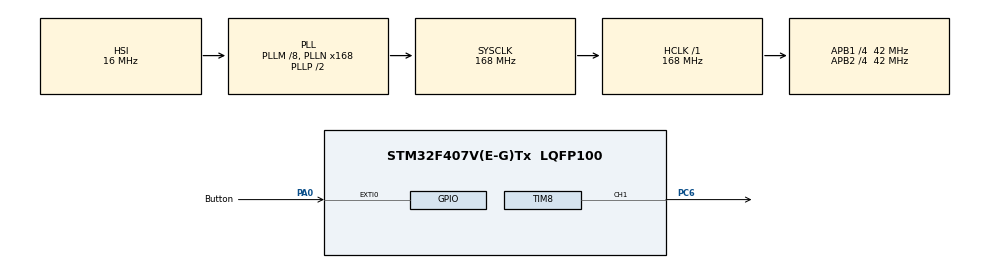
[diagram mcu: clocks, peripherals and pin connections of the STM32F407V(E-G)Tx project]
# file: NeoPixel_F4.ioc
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Dma.Request0=TIM8_CH1
Dma.TIM8_CH1.0.Direction=DMA_MEMORY_TO_PERIPH
Dma.TIM8_CH1.0.FIFOMode=DMA_FIFOMODE_DISABLE
Dma.TIM8_CH1.0.Instance=DMA2_Stream2
Dma.TIM8_CH1.0.MemDataAlignment=DMA_MDATAALIGN_HALFWORD
Dma.TIM8_CH1.0.MemInc=DMA_MINC_ENABLE
Dma.TIM8_CH1.0.Mode=DMA_CIRCULAR
Dma.TIM8_CH1.0.PeriphDataAlignment=DMA_PDATAALIGN_HALFWORD
Dma.TIM8_CH1.0.PeriphInc=DMA_PINC_DISABLE
Dma.TIM8_CH1.0.Priority=DMA_PRIORITY_HIGH
Mcu.Family=STM32F4
Mcu.Name=STM32F407V(E-G)Tx
Mcu.Package=LQFP100
NVIC.DMA2_Stream2_IRQn=true\:0\:0\:false\:false\:true\:false\:true
NVIC.PriorityGroup=NVIC_PRIORITYGROUP_4
PA0-WKUP.GPIO_Label=Button
PA0-WKUP.Signal=GPXTI0
PA13.Mode=Serial_Wire
PA13.Signal=SYS_JTMS-SWDIO
PA14.Mode=Serial_Wire
PA14.Signal=SYS_JTCK-SWCLK
PC14-OSC32_IN.Mode=LSE-External-Oscillator
PC14-OSC32_IN.Signal=RCC_OSC32_IN
PC15-OSC32_OUT.Mode=LSE-External-Oscillator
PC15-OSC32_OUT.Signal=RCC_OSC32_OUT
PC6.GPIO_PuPd=GPIO_PULLDOWN
PC6.GPIO_Speed=GPIO_SPEED_FREQ_HIGH
PC6.Signal=S_TIM8_CH1
PH0-OSC_IN.Mode=HSE-External-Oscillator
PH0-OSC_IN.Signal=RCC_OSC_IN
PH1-OSC_OUT.Mode=HSE-External-Oscillator
PH1-OSC_OUT.Signal=RCC_OSC_OUT
ProjectManager.HeapSize=0x200
ProjectManager.StackSize=0x400
ProjectManager.TargetToolchain=STM32CubeIDE
RCC.48MHZClocksFreq_Value=84000000
RCC.AHBFreq_Value=168000000
RCC.APB1CLKDivider=RCC_HCLK_DIV4
RCC.APB1Freq_Value=42000000
RCC.APB1TimFreq_Value=84000000
RCC.APB2CLKDivider=RCC_HCLK_DIV4
RCC.APB2Freq_Value=42000000
RCC.APB2TimFreq_Value=84000000
RCC.CortexFreq_Value=168000000
RCC.HCLKFreq_Value=168000000
RCC.HSE_VALUE=25000000
RCC.HSI_VALUE=16000000
RCC.PLLM=8
RCC.PLLN=168
RCC.SYSCLKFreq_VALUE=168000000
RCC.SYSCLKSource=RCC_SYSCLKSOURCE_PLLCLK
RCC.VCOOutputFreq_Value=336000000
SH.S_TIM8_CH1.0=TIM8_CH1,PWM Generation1 CH1
TIM8.Channel-PWM\ Generation1\ CH1=TIM_CHANNEL_1
TIM8.OC1Preload_PWM=ENABLE
TIM8.OCFastMode_PWM-PWM\ Generation1\ CH1=TIM_OCFAST_ENABLE
TIM8.OCMode_PWM-PWM\ Generation1\ CH1=TIM_OCMODE_PWM2
TIM8.OCPolarity_1=TIM_OCPOLARITY_LOW
TIM8.Period=104
TIM8.TIM_MasterOutputTrigger=TIM_TRGO_RESET
VP_TIM8_VS_ClockSourceINT.Mode=Internal
board=custom

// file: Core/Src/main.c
/* USER CODE BEGIN Header */
/**
  ******************************************************************************
  * @file           : main.c
  * @brief          : Main program body
  ******************************************************************************
  * @attention
  *
  * <h2><center>&copy; Copyright (c) 2020 STMicroelectronics.
  * All rights reserved.</center></h2>
  *
  * This software component is licensed by ST under BSD 3-Clause license,
  * the "License"; You may not use this file except in compliance with the
  * License. You may obtain a copy of the License at:
  *                        opensource.org/licenses/BSD-3-Clause
  *
  ******************************************************************************
  */
/* USER CODE END Header */
#include "main.h"

/* USER CODE BEGIN Includes */
#include "Neopixel/neopixel.h"
/* USER CODE END Includes */

/* USER CODE BEGIN PD */
#define NUMBERLEDS		5
/* USER CODE END PD */

TIM_HandleTypeDef htim8;
DMA_HandleTypeDef hdma_tim8_ch1;

/* USER CODE BEGIN PV */

uint8_t nums_bit=0;

color database[NUMBERLEDS];

/* USER CODE END PV */

void SystemClock_Config(void);
static void MX_GPIO_Init(void);
static void MX_DMA_Init(void);
static void MX_TIM8_Init(void);

/* USER CODE BEGIN 0 */
void HAL_GPIO_EXTI_Callback(uint16_t GPIO_Pin)
{
	if(GPIO_Pin==GPIO_PIN_0)
	{
		__NOP();
	}
}

/* USER CODE END 0 */

int main(void)
{

  /* MCU Configuration--------------------------------------------------------*/

  /* Reset of all peripherals, Initializes the Flash interface and the Systick. */
  HAL_Init();

  /* Configure the system clock */
  SystemClock_Config();

  /* Initialize all configured peripherals */
  MX_GPIO_Init();
  MX_DMA_Init();
  MX_TIM8_Init();
  /* USER CODE BEGIN 2 */
  init_neopixel(WS2812);
  all_black_render();
  /* USER CODE END 2 */

  /* Infinite loop */
  while (1)
  {

    /* USER CODE BEGIN 3 */
	  if(mode==HALT)
	  {
		  render_rainbow_cycle_mode(5);
	  }
  }
  /* USER CODE END 3 */
}

void SystemClock_Config(void)
{
  RCC_OscInitTypeDef RCC_OscInitStruct = {0};
  RCC_ClkInitTypeDef RCC_ClkInitStruct = {0};

  /** Configure the main internal regulator output voltage
  */
  __HAL_RCC_PWR_CLK_ENABLE();
  __HAL_PWR_VOLTAGESCALING_CONFIG(PWR_REGULATOR_VOLTAGE_SCALE1);
  /** Initializes the RCC Oscillators according to the specified parameters
  * in the RCC_OscInitTypeDef structure.
  */
  RCC_OscInitStruct.OscillatorType = RCC_OSCILLATORTYPE_HSI;
  RCC_OscInitStruct.HSIState = RCC_HSI_ON;
  RCC_OscInitStruct.HSICalibrationValue = RCC_HSICALIBRATION_DEFAULT;
  RCC_OscInitStruct.PLL.PLLState = RCC_PLL_ON;
  RCC_OscInitStruct.PLL.PLLSource = RCC_PLLSOURCE_HSI;
  RCC_OscInitStruct.PLL.PLLM = 8;
  RCC_OscInitStruct.PLL.PLLN = 168;
  RCC_OscInitStruct.PLL.PLLP = RCC_PLLP_DIV2;
  RCC_OscInitStruct.PLL.PLLQ = 4;
  if (HAL_RCC_OscConfig(&RCC_OscInitStruct) != HAL_OK)
  {
    Error_Handler();
  }
  /** Initializes the CPU, AHB and APB buses clocks
  */
  RCC_ClkInitStruct.ClockType = RCC_CLOCKTYPE_HCLK|RCC_CLOCKTYPE_SYSCLK
                              |RCC_CLOCKTYPE_PCLK1|RCC_CLOCKTYPE_PCLK2;
  RCC_ClkInitStruct.SYSCLKSource = RCC_SYSCLKSOURCE_PLLCLK;
  RCC_ClkInitStruct.AHBCLKDivider = RCC_SYSCLK_DIV1;
  RCC_ClkInitStruct.APB1CLKDivider = RCC_HCLK_DIV4;
  RCC_ClkInitStruct.APB2CLKDivider = RCC_HCLK_DIV4;

  if (HAL_RCC_ClockConfig(&RCC_ClkInitStruct, FLASH_LATENCY_5) != HAL_OK)
  {
    Error_Handler();
  }
}

static void MX_TIM8_Init(void)
{

  TIM_ClockConfigTypeDef sClockSourceConfig = {0};
  TIM_MasterConfigTypeDef sMasterConfig = {0};
  TIM_OC_InitTypeDef sConfigOC = {0};
  TIM_BreakDeadTimeConfigTypeDef sBreakDeadTimeConfig = {0};

  htim8.Instance = TIM8;
  htim8.Init.Prescaler = 0;
  htim8.Init.CounterMode = TIM_COUNTERMODE_UP;
  htim8.Init.Period = 104;
  htim8.Init.ClockDivision = TIM_CLOCKDIVISION_DIV1;
  htim8.Init.RepetitionCounter = 0;
  htim8.Init.AutoReloadPreload = TIM_AUTORELOAD_PRELOAD_DISABLE;
  if (HAL_TIM_Base_Init(&htim8) != HAL_OK)
  {
    Error_Handler();
  }
  sClockSourceConfig.ClockSource = TIM_CLOCKSOURCE_INTERNAL;
  if (HAL_TIM_ConfigClockSource(&htim8, &sClockSourceConfig) != HAL_OK)
  {
    Error_Handler();
  }
  if (HAL_TIM_PWM_Init(&htim8) != HAL_OK)
  {
    Error_Handler();
  }
  sMasterConfig.MasterOutputTrigger = TIM_TRGO_RESET;
  sMasterConfig.MasterSlaveMode = TIM_MASTERSLAVEMODE_DISABLE;
  if (HAL_TIMEx_MasterConfigSynchronization(&htim8, &sMasterConfig) != HAL_OK)
  {
    Error_Handler();
  }
  sConfigOC.OCMode = TIM_OCMODE_PWM2;
  sConfigOC.Pulse = 0;
  sConfigOC.OCPolarity = TIM_OCPOLARITY_LOW;
  sConfigOC.OCNPolarity = TIM_OCNPOLARITY_HIGH;
  sConfigOC.OCFastMode = TIM_OCFAST_ENABLE;
  sConfigOC.OCIdleState = TIM_OCIDLESTATE_RESET;
  sConfigOC.OCNIdleState = TIM_OCNIDLESTATE_RESET;
  if (HAL_TIM_PWM_ConfigChannel(&htim8, &sConfigOC, TIM_CHANNEL_1) != HAL_OK)
  {
    Error_Handler();
  }
  sBreakDeadTimeConfig.OffStateRunMode = TIM_OSSR_DISABLE;
  sBreakDeadTimeConfig.OffStateIDLEMode = TIM_OSSI_DISABLE;
  sBreakDeadTimeConfig.LockLevel = TIM_LOCKLEVEL_OFF;
  sBreakDeadTimeConfig.DeadTime = 0;
  sBreakDeadTimeConfig.BreakState = TIM_BREAK_DISABLE;
  sBreakDeadTimeConfig.BreakPolarity = TIM_BREAKPOLARITY_HIGH;
  sBreakDeadTimeConfig.AutomaticOutput = TIM_AUTOMATICOUTPUT_DISABLE;
  if (HAL_TIMEx_ConfigBreakDeadTime(&htim8, &sBreakDeadTimeConfig) != HAL_OK)
  {
    Error_Handler();
  }
  HAL_TIM_MspPostInit(&htim8);

}

static void MX_DMA_Init(void)
{

  /* DMA controller clock enable */
  __HAL_RCC_DMA2_CLK_ENABLE();

  /* DMA interrupt init */
  /* DMA2_Stream2_IRQn interrupt configuration */
  HAL_NVIC_SetPriority(DMA2_Stream2_IRQn, 0, 0);
  HAL_NVIC_EnableIRQ(DMA2_Stream2_IRQn);

}

static void MX_GPIO_Init(void)
{
  GPIO_InitTypeDef GPIO_InitStruct = {0};

  /* GPIO Ports Clock Enable */
  __HAL_RCC_GPIOC_CLK_ENABLE();
  __HAL_RCC_GPIOH_CLK_ENABLE();
  __HAL_RCC_GPIOA_CLK_ENABLE();

  /*Configure GPIO pin : Button_Pin */
  GPIO_InitStruct.Pin = Button_Pin;
  GPIO_InitStruct.Mode = GPIO_MODE_IT_RISING;
  GPIO_InitStruct.Pull = GPIO_NOPULL;
  HAL_GPIO_Init(Button_GPIO_Port, &GPIO_InitStruct);

}

void Error_Handler(void)
{
  __disable_irq();
  while (1)
  {
  }
}

/************************ (C) COPYRIGHT STMicroelectronics *****END OF FILE****/
